# RL6845_IP_SVD register map
Vendor: Realtek
Registers are 32-bit, read-write, reset 0x0 unless marked. A register's access mark holds for its fields unless they carry their own. Offsets are from the block's base; [hi:lo] are bit positions; <NAME> marks a mode.

## otpc
Base 0x41000000
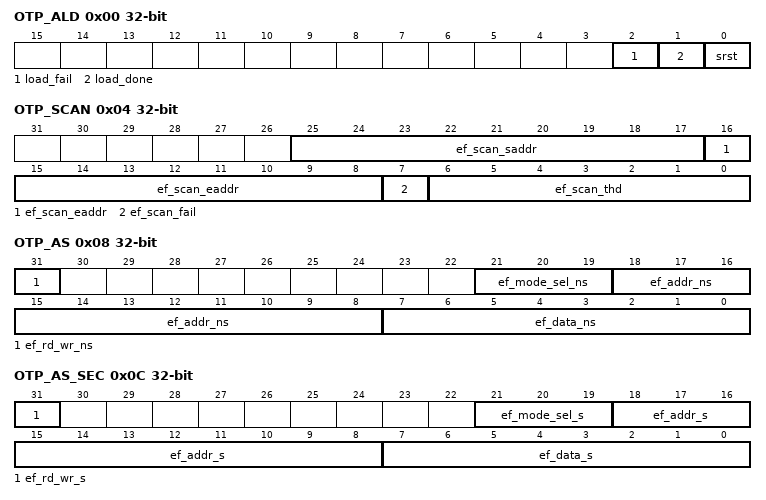
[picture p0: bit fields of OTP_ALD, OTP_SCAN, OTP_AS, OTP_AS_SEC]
0x00 OTP_ALD access per field
  [2] load_fail ro — Autoload fail flag
  [1] load_done ro — Autoload done flag
  [0] srst rw — Soft reset data path except register
0x04 OTP_SCAN access per field
  [25:17] ef_scan_saddr rw — EFuse Scan start Address (unit in byte)
  [16:8] ef_scan_eaddr rw — EFuse Scan End address
  [7] ef_scan_fail ro — Test Scan Report 1: Fail 0: Ok
  [6:0] ef_scan_thd rw — Write this field will trig a scan operation
0x08 OTP_AS
  [31] ef_rd_wr_ns — Write this bit will trig an indirect read or write. Write 1: trigger write write 0: trigger read After this operation done, this bit will toggle.
  [21:19] ef_mode_sel_ns — OTP Mode Selection 000: User Mode 001: Initial Margin Read Mode(room temp) 010: Program Margin Read Mode(room temp) 011: Initial Margin Read Mode(high temp) 100: Program Margin Read Mode(high temp)
  [18:8] ef_addr_ns — OTP indirect read or write address
  [7:0] ef_data_ns — OTP indirect read or write data
0x0C OTP_AS_SEC
  [31] ef_rd_wr_s — Write this bit will trig an indirect read or write. Write 1: trigger write write 0: trigger read After this operation done, this bit will toggle.
  [21:19] ef_mode_sel_s — OTP Mode Selection 000: User Mode 001: Initial Margin Read Mode(room temp) 010: Program Margin Read Mode(room temp) 011: Initial Margin Read Mode(high temp) 100: Program Margin Read Mode(high temp)
  [18:8] ef_addr_s — OTP indirect read or write address
  [7:0] ef_data_s — OTP indirect read or write data
0x10 OTP_TEST_MODE
  [3:0] ef_mode — OTP Test Mode Selection 0000: User Read Mode 0001: Initial Margin Read Mode(room temp) 0010: Program Margin Read Mode(room temp) 0011: Initial Margin Read Mode(high temp) 0100: Program Margin Read Mode(high temp) 0101: User Write Mode 1001: Repair Margin Read Mode 1010: Repair Check Mode 1011: Repair Program Mode Bit[3]=0: User mode and Test mode Bit[3]=1: Use Repair mode
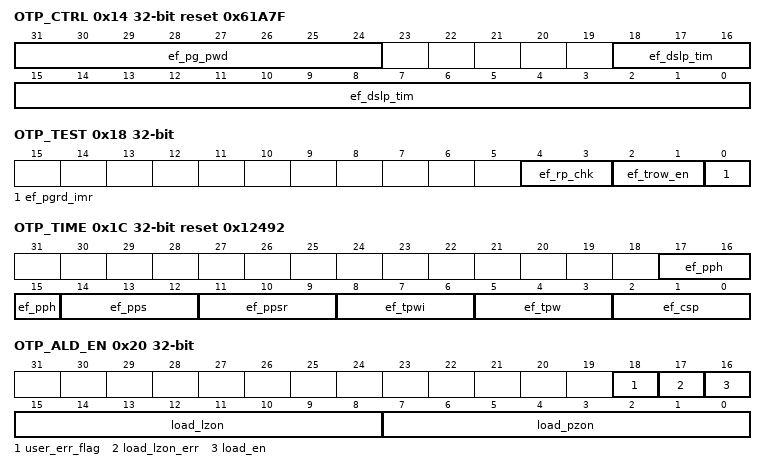
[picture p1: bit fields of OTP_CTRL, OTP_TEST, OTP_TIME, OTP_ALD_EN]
0x14 OTP_CTRL reset 0x61A7F
  [31:24] ef_pg_pwd — OTP program password. OTP can be programed only when this value is 8'h69.
  [18:0] ef_dslp_tim — OTP auto return back to dslp if no operation during ef_dslp_tim (40Mhz)
0x18 OTP_TEST access per field
  [4:3] ef_rp_chk ro — Check result 2'b00: Good sample 2'b01: Repairable sample 2'b11: Failure sample
  [2:1] ef_trow_en rw — Test row enable 2'b01: test row enable 2'b10: test column enable
  [0] ef_pgrd_imr rw — When using mode selection under OTP_Test , this signal needs to be raised to mask mode selection in OTP_AS_SEC/OTP_AS to avoid mode conflict 0: Unmask Program Margin Read Mode and Initial Margin Read Mode of OTP_AS_SEC/OTP_AS register 1: Mask Program Margin Read Mode and Initial Margin Read Mode of OTP_AS_SEC/OTP_AS register
0x1C OTP_TIME reset 0x12492
  [17:15] ef_pph — OTP Program Hold time. In the unit of cycle time (5us< Tpph <20us) For input clock 20 MHz/26 MHz 0: 4us 1: 6us 2: 8us (default) 3: 10us 4: 12us 5: 14us 6: 18us 7: 21us
  [14:12] ef_pps — OTP Program Setup time time. In the unit of cycle time (5us< Tpps<20us) For input clock 20 MHz/26 MHz 0: 4us 1: 6us 2: 8us (default) 3: 10us 4: 12us 5: 14us 6: 18us 7: 21us
  [11:9] ef_ppsr — OTP Program Recovery time. In the unit of cycle time (5us< Tppr<100us) For input clock 20 MHz/26 MHz 0: 4us 1: 15us 2: 30us (default) 3: 45us 4: 60us 5: 75us 6: 90us 7: 101us
  [8:6] ef_tpwi — Program Pulse Interval Time (1us<ef_tpwi<5us) For input clock 20 MHz/26 MHz 0: 0.5us 1: 1.5us 2: 2us (default) 3: 2.5us 4: 3us 5: 3.5us 6: 4us 7: 5.5us
  [5:3] ef_tpw — Program pulse width time.OTP Program Pulse width Time (20us<ef_tpw<25us) For input clock 20 MHz/26 MHz 0: 19.5us 1: 23us 2: 23.5us (default) 3: 24us 4: 24.5us 5: 25.5us
  [2:0] ef_csp — IP enable time in program (10us<ef_csp<100us) For input clock 20 MHz/26 MHz 0: 5us 1: 15us 2: 30us (default) 3: 45us 4: 60us 5: 75us 6: 90us 7: 101us
0x20 OTP_ALD_EN access per field
  [18] user_err_flag ro — When the autoload format in the user zone is incorrectly written, the signal will be raised.
  [17] load_lzon_err ro — When the actual autoload data in the logical region is larger than the planned physical interval, this error signal will be high
  [16] load_en rw — Soft load enable, write one auto clear
  [15:8] load_lzon rw — Logic load zone select (currently only supports software to trigger autoload in rom area) 0bit: 11'h0 - 11'h7 system data 1bit: 11'h8 - 11'h1F AON hareware data 2bit: 11'h140 - 11'h1AF LS hareware data 3bit: 11'h300 - 11'h32F AON pmc patch 4bit: 11'h340 - 11'h36F LS pmc patch 5bit: 11'h380 - 11'h3FF AON register patch 6bit: 11'h400 - 11'h47F LS register patch 7bit: It's invalid to write 1 or 0.
  [7:0] load_pzon rw — physical load zone select
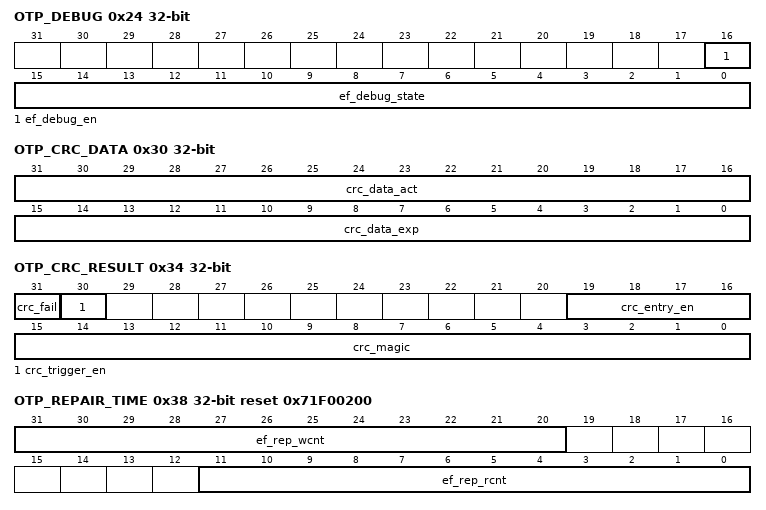
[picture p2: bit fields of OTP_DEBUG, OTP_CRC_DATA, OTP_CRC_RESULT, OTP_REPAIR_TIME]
0x24 OTP_DEBUG access per field
  [16] ef_debug_en rw — Debug enable
  [15:0] ef_debug_state ro — State machine operating state [8:5]: autoload state. [4:3]: rd/wr ctrl state. [2:0]: wav state.Working status of different modes.
0x30 OTP_CRC_DATA ro
  [31:16] crc_data_act — Actual crc data by hw calurate . Note : even CRC disabled by crc entry , this value will also get by hw.
  [15:0] crc_data_exp — Expect crc data from physical zone
0x34 OTP_CRC_RESULT access per field
  [31] crc_fail ro — CRC compare fail flag . If CRC is disable by CRC_ENTRY , this bit will be 0
  [30] crc_trigger_en rw — The software enables calculation of the CRC in the secure zone and returns the calculated value(200-36f)
  [19:16] crc_entry_en ro — one-hot bit for CRC_entry enable flag . If this value is 0 , it means CRC is disabled
  [15:0] crc_magic ro — magic data read from valid CRC entry
0x38 OTP_REPAIR_TIME reset 0x71F00200
  [31:20] ef_rep_wcnt — Configure the maximum address in Repair Program Mode.The default values are usually used. Please do not change them arbitrarily
  [11:0] ef_rep_rcnt — Configure the maximum address to read in both read modes of REPAIR (Repair Margin Read Mode, Repair Check Mode ) 1. for Repair Margin Read Mode, ef_rep_rcnt is 12'd513 2.for Repair Check Mode, er _rep_rcnt is 12'd0
0x3C OTP_HID_PRO wo
  [31:0] hid_pro_w_pwd — to protect hidden zone
0x40 OTP_PARAM
  [31:0] dummy — TO DO
